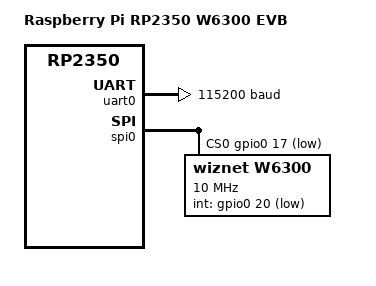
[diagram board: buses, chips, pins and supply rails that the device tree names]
/dts-v1/;

/* 
 * NOTE: We assume generic RP2350 support is available. 
 * You might need to adjust the include if the RP2350 dtsi is named differently.
 */
#include <rpi_pico/rp2350.dtsi> 

/ {
	model = "Raspberry Pi RP2350 W6300 EVB";
	compatible = "raspberrypi,rp2350-w6300-evb";

	chosen {
		zephyr,sram = &sram0;
		zephyr,flash = &flash0;
		zephyr,console = &uart0;
		zephyr,shell-uart = &uart0;
	};
};

&uart0 {
	status = "okay";
	current-speed = <115200>;
};

&spi0 {
	status = "okay";
	/* 
	 * TODO: Check your schematic!
	 * Update cs-gpios to match the Chip Select pin for W6300.
	 */
	cs-gpios = <&gpio0 17 GPIO_ACTIVE_LOW>; 

	w6300: w6300@0 {
		compatible = "wiznet,w6300";
		reg = <0>;
		spi-max-frequency = <10000000>;
		/* 
		 * TODO: Check your schematic! 
		 * Update int-gpios to match the Interrupt pin from W6300.
		 */
		int-gpios = <&gpio0 20 GPIO_ACTIVE_LOW>; 
	};
};
